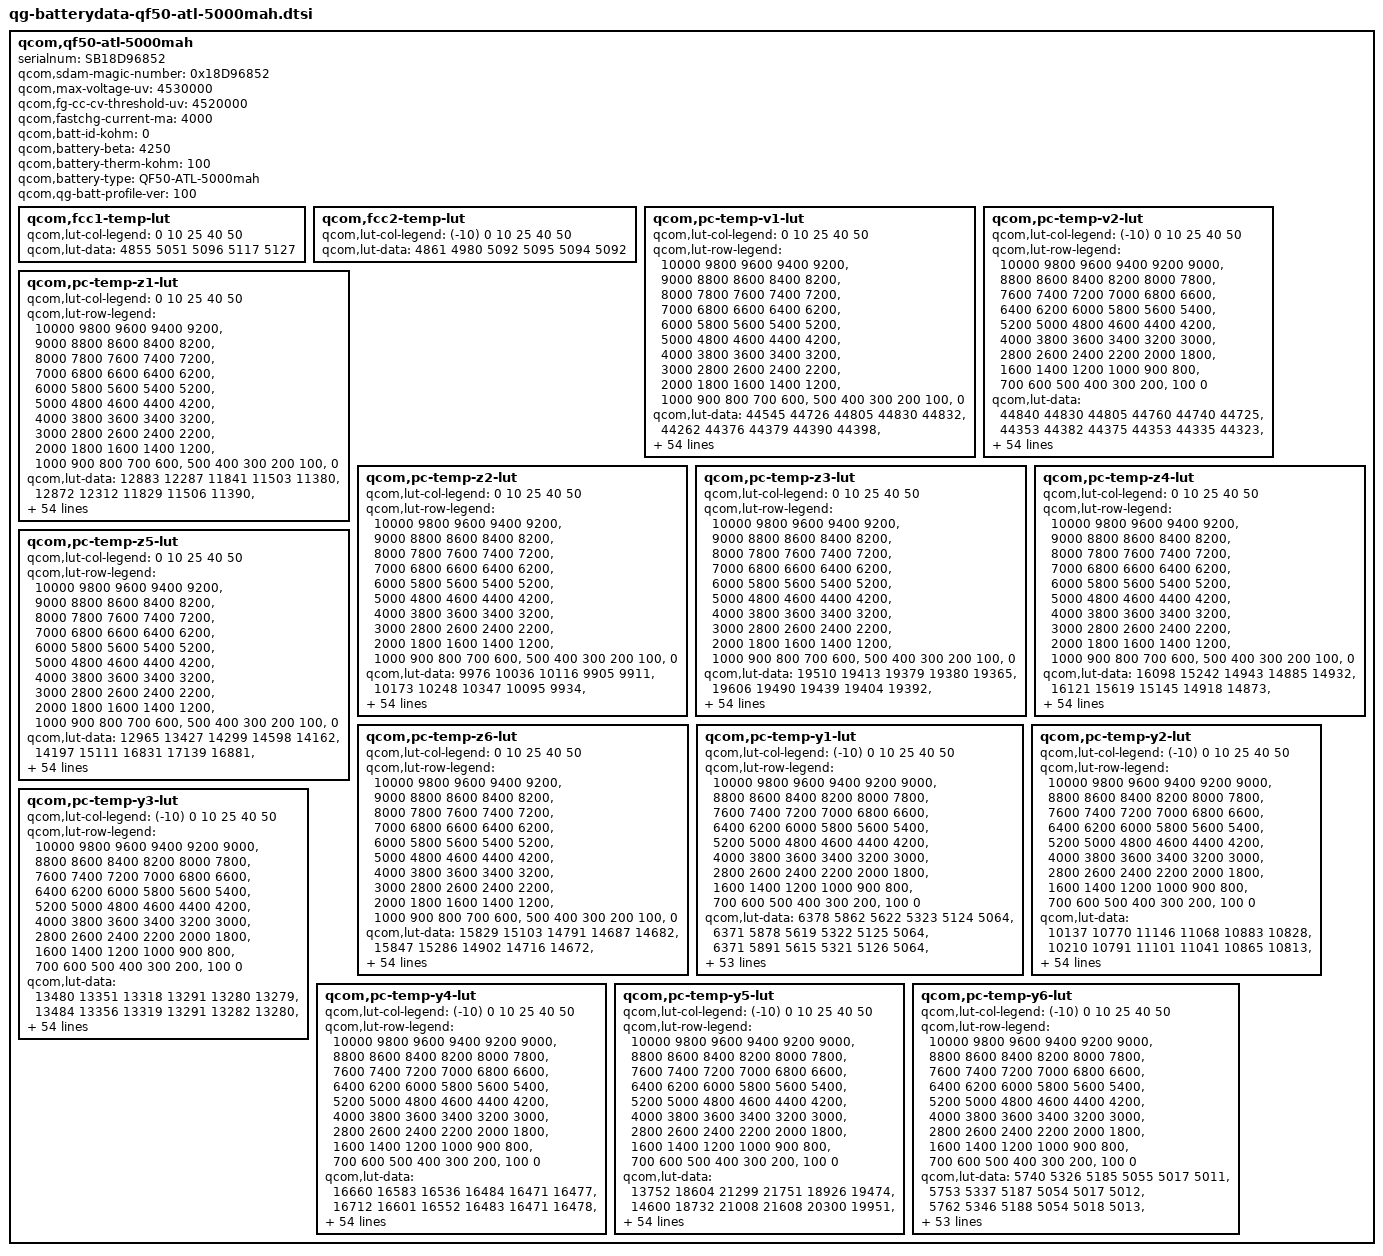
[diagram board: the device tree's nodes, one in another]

qcom,qf50-atl-5000mah {
    /* ATL_5000mAH_averaged_MasterSlave_Aug11th2023 */
    serialnum = "SB18D96852";
    qcom,sdam-magic-number = <0x18D96852>;
    qcom,max-voltage-uv = <4530000>;
    qcom,fg-cc-cv-threshold-uv = <4520000>;
    qcom,fastchg-current-ma = <4000>;
    qcom,batt-id-kohm = <0>;
    qcom,battery-beta = <4250>;
    qcom,battery-therm-kohm = <100>;
    qcom,battery-type = "QF50-ATL-5000mah";
    qcom,qg-batt-profile-ver = <100>;

	qcom,fcc1-temp-lut {
		qcom,lut-col-legend = <0 10 25 40 50>;
		qcom,lut-data = <4855 5051 5096 5117 5127>;
	};

	qcom,fcc2-temp-lut {
		qcom,lut-col-legend = <(-10) 0 10 25 40 50>;
		qcom,lut-data = <4861 4980 5092 5095 5094 5092>;
	};

	qcom,pc-temp-v1-lut {
		qcom,lut-col-legend = <0 10 25 40 50>;
		qcom,lut-row-legend = <10000 9800 9600 9400 9200>,
			<9000 8800 8600 8400 8200>,
			<8000 7800 7600 7400 7200>,
			<7000 6800 6600 6400 6200>,
			<6000 5800 5600 5400 5200>,
			<5000 4800 4600 4400 4200>,
			<4000 3800 3600 3400 3200>,
			<3000 2800 2600 2400 2200>,
			<2000 1800 1600 1400 1200>,
			<1000 900 800 700 600>,
			<500 400 300 200 100>,
			<0>;
		qcom,lut-data = <44545 44726 44805 44830 44832>,
			<44262 44376 44379 44390 44398>,
			<44026 44128 44112 44109 44110>,
			<43813 43903 43890 43882 43873>,
			<43593 43676 43664 43656 43646>,
			<43363 43455 43443 43433 43427>,
			<43128 43220 43216 43207 43206>,
			<42888 42974 42976 42969 42971>,
			<42641 42725 42729 42725 42725>,
			<42397 42479 42480 42479 42479>,
			<42157 42232 42228 42228 42232>,
			<41920 41987 41981 41981 41988>,
			<41688 41740 41737 41741 41746>,
			<41460 41501 41499 41505 41507>,
			<41239 41271 41269 41273 41276>,
			<41027 41048 41045 41045 41049>,
			<40821 40835 40831 40827 40830>,
			<40622 40630 40625 40619 40619>,
			<40431 40435 40429 40421 40418>,
			<40247 40252 40246 40239 40231>,
			<40068 40073 40071 40068 40057>,
			<39895 39890 39880 39875 39863>,
			<39720 39707 39668 39640 39625>,
			<39547 39499 39453 39408 39391>,
			<39369 39224 39229 39209 39202>,
			<39165 38972 39016 39028 39037>,
			<38941 38840 38875 38890 38896>,
			<38775 38751 38780 38786 38775>,
			<38672 38666 38692 38690 38668>,
			<38591 38580 38598 38587 38568>,
			<38519 38501 38509 38488 38478>,
			<38454 38426 38427 38405 38398>,
			<38397 38355 38350 38333 38326>,
			<38343 38293 38280 38265 38257>,
			<38296 38240 38221 38201 38189>,
			<38255 38191 38166 38139 38121>,
			<38221 38150 38112 38074 38051>,
			<38185 38112 38060 38009 37980>,
			<38142 38060 37996 37930 37894>,
			<38093 37985 37913 37827 37773>,
			<38025 37892 37814 37711 37639>,
			<37921 37780 37699 37600 37520>,
			<37798 37643 37564 37481 37401>,
			<37656 37475 37401 37317 37231>,
			<37490 37310 37241 37169 37087>,
			<37317 37180 37126 37073 37011>,
			<37241 37134 37083 37040 36983>,
			<37181 37107 37054 37014 36958>,
			<37141 37077 37027 36988 36930>,
			<37106 37042 36985 36943 36876>,
			<37060 36899 36816 36724 36630>,
			<37006 36480 36387 36301 36201>,
			<36858 35880 35800 35725 35623>,
			<36390 35022 34993 34937 34829>,
			<35518 33587 33735 33717 33593>,
			<30000 30000 30000 30000 30000>;
	};

	qcom,pc-temp-v2-lut {
		qcom,lut-col-legend = <(-10) 0 10 25 40 50>;
		qcom,lut-row-legend = <10000 9800 9600 9400 9200 9000>,
			<8800 8600 8400 8200 8000 7800>,
			<7600 7400 7200 7000 6800 6600>,
			<6400 6200 6000 5800 5600 5400>,
			<5200 5000 4800 4600 4400 4200>,
			<4000 3800 3600 3400 3200 3000>,
			<2800 2600 2400 2200 2000 1800>,
			<1600 1400 1200 1000 900 800>,
			<700 600 500 400 300 200>,
			<100 0>;
		qcom,lut-data = <44840 44830 44805 44760 44740 44725>,
			<44353 44382 44375 44353 44335 44323>,
			<43947 44007 44012 44005 43989 43978>,
			<43649 43725 43735 43730 43714 43704>,
			<43432 43515 43522 43514 43496 43485>,
			<43230 43311 43309 43297 43278 43267>,
			<43003 43082 43076 43063 43044 43035>,
			<42771 42847 42837 42823 42805 42798>,
			<42536 42608 42591 42578 42560 42556>,
			<42295 42361 42338 42327 42307 42309>,
			<42055 42114 42087 42078 42058 42062>,
			<41823 41871 41840 41831 41814 41816>,
			<41598 41631 41595 41588 41574 41573>,
			<41370 41398 41356 41349 41338 41336>,
			<41142 41171 41121 41116 41107 41105>,
			<40909 40952 40895 40890 40882 40880>,
			<40664 40746 40675 40672 40663 40662>,
			<40407 40544 40465 40463 40453 40452>,
			<40154 40317 40274 40265 40257 40254>,
			<39911 40056 40091 40074 40069 40065>,
			<39675 39800 39875 39879 39884 39881>,
			<39460 39563 39604 39680 39709 39712>,
			<39263 39338 39342 39472 39521 39528>,
			<39073 39137 39124 39230 39275 39283>,
			<38882 38953 38928 38982 39010 39017>,
			<38693 38787 38762 38798 38821 38829>,
			<38529 38640 38617 38658 38682 38695>,
			<38381 38506 38488 38537 38563 38576>,
			<38257 38378 38372 38427 38451 38461>,
			<38166 38252 38266 38328 38350 38355>,
			<38094 38142 38169 38236 38261 38262>,
			<38027 38050 38079 38149 38181 38179>,
			<37964 37973 37998 38071 38106 38103>,
			<37904 37909 37927 38000 38036 38038>,
			<37843 37857 37862 37932 37967 37973>,
			<37781 37810 37805 37861 37889 37889>,
			<37718 37763 37755 37789 37804 37787>,
			<37653 37716 37699 37710 37712 37680>,
			<37585 37660 37633 37623 37608 37570>,
			<37513 37590 37557 37531 37501 37460>,
			<37438 37506 37458 37440 37408 37364>,
			<37356 37393 37337 37343 37317 37270>,
			<37264 37259 37199 37217 37199 37149>,
			<37164 37126 37038 37076 37063 37009>,
			<37059 36973 36849 36940 36933 36883>,
			<36958 36815 36735 36866 36870 36821>,
			<36911 36753 36692 36846 36856 36807>,
			<36862 36699 36638 36826 36842 36791>,
			<36813 36653 36569 36796 36817 36764>,
			<36763 36601 36456 36724 36753 36688>,
			<36696 36506 36169 36463 36491 36397>,
			<36614 36313 35546 35958 36008 35899>,
			<36500 35974 34682 35266 35353 35231>,
			<36161 35224 33739 34296 34425 34285>,
			<35888 34573 32388 32686 32977 32845>,
			<35789 33816 28029 28977 28510 28219>;
	};

	qcom,pc-temp-z1-lut {
		qcom,lut-col-legend = <0 10 25 40 50>;
		qcom,lut-row-legend = <10000 9800 9600 9400 9200>,
			<9000 8800 8600 8400 8200>,
			<8000 7800 7600 7400 7200>,
			<7000 6800 6600 6400 6200>,
			<6000 5800 5600 5400 5200>,
			<5000 4800 4600 4400 4200>,
			<4000 3800 3600 3400 3200>,
			<3000 2800 2600 2400 2200>,
			<2000 1800 1600 1400 1200>,
			<1000 900 800 700 600>,
			<500 400 300 200 100>,
			<0>;
		qcom,lut-data = <12883 12287 11841 11503 11380>,
			<12872 12312 11829 11506 11390>,
			<12871 12301 11819 11497 11385>,
			<12878 12287 11813 11491 11381>,
			<12883 12275 11803 11485 11377>,
			<12877 12261 11791 11478 11373>,
			<12865 12243 11779 11472 11370>,
			<12838 12220 11767 11468 11369>,
			<12793 12200 11756 11465 11368>,
			<12766 12182 11751 11463 11367>,
			<12756 12167 11747 11461 11366>,
			<12748 12160 11744 11460 11365>,
			<12733 12155 11741 11459 11364>,
			<12708 12154 11739 11458 11363>,
			<12687 12151 11738 11457 11363>,
			<12670 12147 11738 11456 11363>,
			<12657 12147 11737 11456 11363>,
			<12655 12148 11736 11455 11363>,
			<12664 12149 11736 11455 11364>,
			<12673 12151 11738 11456 11364>,
			<12674 12153 11742 11458 11365>,
			<12672 12156 11743 11458 11365>,
			<12675 12161 11743 11458 11365>,
			<12690 12163 11743 11458 11365>,
			<12706 12163 11746 11459 11365>,
			<12713 12163 11750 11461 11367>,
			<12719 12167 11754 11464 11369>,
			<12723 12177 11758 11467 11371>,
			<12726 12185 11762 11471 11374>,
			<12728 12190 11767 11474 11376>,
			<12735 12194 11772 11477 11379>,
			<12744 12197 11778 11481 11381>,
			<12755 12203 11784 11484 11384>,
			<12771 12208 11790 11488 11387>,
			<12789 12218 11796 11492 11391>,
			<12799 12229 11803 11497 11395>,
			<12806 12241 11808 11502 11399>,
			<12810 12252 11813 11508 11403>,
			<12811 12260 11820 11514 11406>,
			<12811 12266 11830 11519 11410>,
			<12816 12272 11840 11524 11414>,
			<12849 12287 11842 11529 11418>,
			<12874 12304 11844 11534 11422>,
			<12884 12310 11855 11539 11425>,
			<12899 12321 11874 11544 11428>,
			<12928 12334 11880 11547 11430>,
			<12919 12330 11882 11546 11429>,
			<12931 12336 11880 11546 11429>,
			<12944 12332 11889 11548 11431>,
			<12943 12343 11898 11553 11436>,
			<12915 12361 11905 11560 11439>,
			<12947 12371 11921 11567 11446>,
			<12953 12391 11941 11577 11454>,
			<12970 12538 11960 11591 11466>,
			<12970 12538 11960 11591 11466>,
			<12970 12538 11960 11591 11466>;
	};

	qcom,pc-temp-z2-lut {
		qcom,lut-col-legend = <0 10 25 40 50>;
		qcom,lut-row-legend = <10000 9800 9600 9400 9200>,
			<9000 8800 8600 8400 8200>,
			<8000 7800 7600 7400 7200>,
			<7000 6800 6600 6400 6200>,
			<6000 5800 5600 5400 5200>,
			<5000 4800 4600 4400 4200>,
			<4000 3800 3600 3400 3200>,
			<3000 2800 2600 2400 2200>,
			<2000 1800 1600 1400 1200>,
			<1000 900 800 700 600>,
			<500 400 300 200 100>,
			<0>;
		qcom,lut-data = <9976 10036 10116 9905 9911>,
			<10173 10248 10347 10095 9934>,
			<10194 10308 10347 10167 10048>,
			<10200 10326 10338 10176 10191>,
			<10199 10307 10322 10177 10235>,
			<10184 10271 10284 10180 10194>,
			<10164 10244 10243 10176 10141>,
			<10145 10222 10199 10143 10107>,
			<10126 10211 10165 10098 10078>,
			<10112 10353 10163 10085 10055>,
			<10101 10533 10168 10088 10028>,
			<10093 10494 10170 10088 10002>,
			<10092 10288 10164 10064 9973>,
			<10092 10193 10159 10034 9947>,
			<10095 10203 10163 10033 9946>,
			<10104 10215 10172 10044 9963>,
			<10120 10225 10175 10049 9979>,
			<10133 10235 10172 10031 9991>,
			<10144 10245 10170 10011 10001>,
			<10156 10259 10172 10012 10007>,
			<10170 10274 10180 10019 10010>,
			<10186 10287 10196 10041 10023>,
			<10201 10298 10242 10182 10156>,
			<10216 10311 10273 10305 10287>,
			<10231 10328 10247 10240 10242>,
			<10249 10341 10202 10095 10115>,
			<10269 10332 10187 10064 10116>,
			<10277 10303 10182 10126 10483>,
			<10275 10292 10180 10175 10772>,
			<10273 10293 10195 10225 10642>,
			<10273 10296 10219 10296 10359>,
			<10275 10300 10232 10276 10163>,
			<10278 10306 10242 10117 10000>,
			<10283 10312 10245 10015 9930>,
			<10289 10320 10235 10001 9934>,
			<10295 10328 10223 9996 9942>,
			<10300 10336 10224 10008 9960>,
			<10306 10344 10234 10045 10000>,
			<10312 10356 10245 10079 10043>,
			<10320 10374 10262 10109 10094>,
			<10328 10387 10280 10131 10133>,
			<10337 10384 10291 10141 10131>,
			<10347 10381 10301 10145 10123>,
			<10360 10383 10308 10142 10125>,
			<10503 10422 10313 10143 10126>,
			<10531 10479 10301 10140 10100>,
			<10518 10469 10293 10135 10085>,
			<10527 10503 10280 10136 10088>,
			<10600 10539 10269 10144 10104>,
			<10436 10876 10288 10182 10150>,
			<10390 10719 10300 10152 10107>,
			<10160 10449 10263 10060 9980>,
			<10121 10372 10243 10010 9917>,
			<10084 10292 10148 9967 9862>,
			<10084 10292 10148 9967 9862>,
			<10084 10292 10148 9967 9862>;
	};

	qcom,pc-temp-z3-lut {
		qcom,lut-col-legend = <0 10 25 40 50>;
		qcom,lut-row-legend = <10000 9800 9600 9400 9200>,
			<9000 8800 8600 8400 8200>,
			<8000 7800 7600 7400 7200>,
			<7000 6800 6600 6400 6200>,
			<6000 5800 5600 5400 5200>,
			<5000 4800 4600 4400 4200>,
			<4000 3800 3600 3400 3200>,
			<3000 2800 2600 2400 2200>,
			<2000 1800 1600 1400 1200>,
			<1000 900 800 700 600>,
			<500 400 300 200 100>,
			<0>;
		qcom,lut-data = <19510 19413 19379 19380 19365>,
			<19606 19490 19439 19404 19392>,
			<19639 19518 19446 19410 19405>,
			<19658 19530 19448 19410 19410>,
			<19664 19533 19449 19411 19412>,
			<19668 19534 19449 19418 19413>,
			<19670 19534 19448 19423 19413>,
			<19669 19532 19447 19423 19414>,
			<19664 19531 19446 19423 19416>,
			<19659 19536 19444 19422 19416>,
			<19653 19540 19441 19418 19411>,
			<19646 19534 19438 19413 19406>,
			<19640 19515 19435 19408 19403>,
			<19634 19502 19432 19403 19400>,
			<19627 19498 19428 19401 19397>,
			<19618 19496 19425 19399 19394>,
			<19608 19493 19422 19397 19390>,
			<19601 19489 19418 19393 19387>,
			<19594 19486 19415 19389 19383>,
			<19589 19482 19411 19383 19379>,
			<19585 19479 19409 19377 19374>,
			<19582 19478 19409 19375 19372>,
			<19582 19479 19414 19384 19377>,
			<19583 19479 19418 19391 19381>,
			<19584 19486 19415 19384 19375>,
			<19588 19492 19410 19370 19362>,
			<19597 19491 19406 19368 19362>,
			<19601 19484 19402 19378 19400>,
			<19597 19480 19400 19390 19430>,
			<19591 19479 19405 19403 19427>,
			<19588 19479 19413 19414 19420>,
			<19584 19480 19418 19415 19412>,
			<19582 19481 19421 19406 19402>,
			<19580 19482 19423 19397 19392>,
			<19578 19481 19420 19389 19382>,
			<19576 19479 19414 19381 19373>,
			<19573 19477 19410 19374 19364>,
			<19570 19474 19405 19367 19355>,
			<19566 19472 19401 19364 19352>,
			<19561 19468 19400 19366 19354>,
			<19555 19464 19398 19369 19357>,
			<19549 19460 19395 19367 19359>,
			<19543 19456 19392 19364 19362>,
			<19534 19455 19391 19367 19365>,
			<19498 19445 19388 19366 19363>,
			<19484 19429 19379 19359 19356>,
			<19483 19429 19380 19355 19352>,
			<19472 19408 19372 19345 19339>,
			<19381 19390 19369 19343 19335>,
			<19283 19336 19366 19335 19326>,
			<19280 19349 19367 19349 19334>,
			<19268 19425 19382 19364 19353>,
			<19272 19433 19386 19365 19354>,
			<19396 19454 19388 19367 19356>,
			<19396 19454 19388 19367 19356>,
			<19396 19454 19388 19367 19356>;
	};

	qcom,pc-temp-z4-lut {
		qcom,lut-col-legend = <0 10 25 40 50>;
		qcom,lut-row-legend = <10000 9800 9600 9400 9200>,
			<9000 8800 8600 8400 8200>,
			<8000 7800 7600 7400 7200>,
			<7000 6800 6600 6400 6200>,
			<6000 5800 5600 5400 5200>,
			<5000 4800 4600 4400 4200>,
			<4000 3800 3600 3400 3200>,
			<3000 2800 2600 2400 2200>,
			<2000 1800 1600 1400 1200>,
			<1000 900 800 700 600>,
			<500 400 300 200 100>,
			<0>;
		qcom,lut-data = <16098 15242 14943 14885 14932>,
			<16121 15619 15145 14918 14873>,
			<15954 15390 15076 14925 14903>,
			<15633 15166 14953 14869 14858>,
			<15405 15054 14887 14828 14822>,
			<15261 14970 14844 14800 14800>,
			<15149 14909 14812 14778 14782>,
			<15063 14863 14785 14758 14764>,
			<14994 14822 14764 14742 14748>,
			<14938 14774 14745 14732 14741>,
			<14893 14735 14728 14726 14739>,
			<14856 14725 14717 14721 14736>,
			<14824 14727 14712 14717 14733>,
			<14798 14726 14707 14714 14730>,
			<14777 14720 14703 14710 14727>,
			<14760 14714 14699 14706 14724>,
			<14746 14709 14696 14703 14721>,
			<14739 14705 14693 14700 14718>,
			<14734 14701 14691 14697 14715>,
			<14731 14697 14686 14691 14709>,
			<14727 14693 14682 14682 14699>,
			<14722 14694 14683 14681 14697>,
			<14721 14698 14699 14706 14725>,
			<14723 14708 14724 14742 14764>,
			<14728 14760 14764 14778 14793>,
			<14748 14813 14809 14814 14820>,
			<14792 14812 14814 14818 14821>,
			<14813 14795 14799 14790 14765>,
			<14810 14778 14781 14757 14717>,
			<14804 14764 14762 14732 14711>,
			<14797 14750 14742 14711 14708>,
			<14788 14739 14726 14701 14704>,
			<14778 14730 14714 14697 14699>,
			<14771 14723 14705 14692 14693>,
			<14764 14720 14700 14685 14686>,
			<14756 14716 14695 14679 14679>,
			<14748 14712 14692 14676 14675>,
			<14739 14707 14689 14673 14672>,
			<14728 14702 14688 14673 14671>,
			<14716 14699 14688 14682 14686>,
			<14706 14695 14688 14691 14703>,
			<14698 14688 14686 14689 14699>,
			<14689 14678 14680 14683 14689>,
			<14676 14670 14675 14685 14696>,
			<14659 14656 14663 14680 14695>,
			<14660 14644 14649 14657 14663>,
			<14662 14639 14643 14653 14655>,
			<14671 14652 14639 14648 14649>,
			<14771 14666 14628 14631 14632>,
			<14877 14720 14621 14621 14619>,
			<14877 14707 14627 14641 14662>,
			<14889 14638 14639 14662 14685>,
			<14886 14642 14644 14671 14697>,
			<14789 14655 14653 14678 14705>,
			<14789 14655 14653 14678 14705>,
			<14789 14655 14653 14678 14705>;
	};

	qcom,pc-temp-z5-lut {
		qcom,lut-col-legend = <0 10 25 40 50>;
		qcom,lut-row-legend = <10000 9800 9600 9400 9200>,
			<9000 8800 8600 8400 8200>,
			<8000 7800 7600 7400 7200>,
			<7000 6800 6600 6400 6200>,
			<6000 5800 5600 5400 5200>,
			<5000 4800 4600 4400 4200>,
			<4000 3800 3600 3400 3200>,
			<3000 2800 2600 2400 2200>,
			<2000 1800 1600 1400 1200>,
			<1000 900 800 700 600>,
			<500 400 300 200 100>,
			<0>;
		qcom,lut-data = <12965 13427 14299 14598 14162>,
			<14197 15111 16831 17139 16881>,
			<14976 16289 17916 18251 17987>,
			<15573 17257 19012 19376 20816>,
			<16190 18104 19766 20671 22696>,
			<16878 18859 20356 22263 23560>,
			<17607 19647 20893 23734 24390>,
			<18350 20499 21471 24825 25921>,
			<19108 21574 22174 25761 27740>,
			<19899 23985 23185 26731 28317>,
			<20702 26450 24577 27838 28254>,
			<21576 26719 25687 28354 28202>,
			<22683 25813 26520 28224 28415>,
			<24071 25586 27183 28036 28820>,
			<25348 26395 27789 28507 29349>,
			<26528 27485 28481 30364 30177>,
			<27659 28480 28698 31566 31124>,
			<28323 29487 28955 32297 32156>,
			<28918 30465 29368 32854 33334>,
			<29457 31306 29945 32813 34706>,
			<30224 32235 30923 32573 36304>,
			<31850 33678 32692 32873 37911>,
			<33940 35780 36964 38189 40035>,
			<37158 38040 39732 42972 41538>,
			<41164 40979 36175 37180 36321>,
			<46372 43157 29366 24649 23829>,
			<52756 40834 25450 21008 20826>,
			<55183 33836 22731 20996 28485>,
			<50950 30752 21629 21392 35276>,
			<44837 30389 22615 25642 36515>,
			<41943 30228 24676 31967 36967>,
			<40070 31161 27321 32995 36403>,
			<39300 33936 31180 32446 34563>,
			<39452 36386 34044 32061 33005>,
			<39801 38503 35848 31943 32123>,
			<40135 40234 37016 31870 31422>,
			<40447 41422 37323 31939 30898>,
			<40808 42368 37415 32326 30323>,
			<41670 42739 37562 33084 30430>,
			<42961 42672 37794 37099 34033>,
			<43476 42276 37940 41001 37775>,
			<43039 40638 36440 38028 36990>,
			<42255 38817 33859 31822 34900>,
			<39980 41049 35209 35119 38355>,
			<38092 41263 37404 37168 40748>,
			<35083 36672 33177 33602 35286>,
			<33187 36846 33752 28519 29488>,
			<30194 23579 28263 23452 22318>,
			<20593 20631 29284 27160 24830>,
			<11533 13570 30890 26623 27880>,
			<11458 14208 29296 38678 29186>,
			<11281 33440 32439 26555 21352>,
			<11866 33621 30786 21742 17793>,
			<26696 45036 26861 18658 15426>,
			<26696 45036 26861 18658 15426>,
			<26696 45036 26861 18658 15426>;
	};

	qcom,pc-temp-z6-lut {
		qcom,lut-col-legend = <0 10 25 40 50>;
		qcom,lut-row-legend = <10000 9800 9600 9400 9200>,
			<9000 8800 8600 8400 8200>,
			<8000 7800 7600 7400 7200>,
			<7000 6800 6600 6400 6200>,
			<6000 5800 5600 5400 5200>,
			<5000 4800 4600 4400 4200>,
			<4000 3800 3600 3400 3200>,
			<3000 2800 2600 2400 2200>,
			<2000 1800 1600 1400 1200>,
			<1000 900 800 700 600>,
			<500 400 300 200 100>,
			<0>;
		qcom,lut-data = <15829 15103 14791 14687 14682>,
			<15847 15286 14902 14716 14672>,
			<15777 15187 14872 14721 14689>,
			<15616 15086 14816 14695 14672>,
			<15494 15029 14784 14678 14658>,
			<15413 14984 14762 14668 14649>,
			<15347 14948 14744 14660 14641>,
			<15291 14919 14729 14652 14634>,
			<15242 14894 14717 14644 14629>,
			<15201 14871 14705 14638 14625>,
			<15166 14851 14695 14633 14620>,
			<15135 14836 14688 14628 14617>,
			<15108 14824 14683 14623 14613>,
			<15084 14815 14679 14619 14610>,
			<15064 14809 14675 14615 14607>,
			<15046 14805 14671 14612 14603>,
			<15032 14800 14668 14609 14600>,
			<15024 14796 14664 14606 14597>,
			<15020 14792 14661 14602 14593>,
			<15017 14788 14658 14596 14588>,
			<15015 14786 14655 14589 14581>,
			<15014 14786 14656 14588 14579>,
			<15014 14789 14665 14604 14594>,
			<15016 14795 14679 14622 14613>,
			<15022 14822 14695 14634 14621>,
			<15036 14849 14712 14643 14626>,
			<15061 14849 14714 14644 14627>,
			<15072 14839 14707 14638 14625>,
			<15071 14832 14699 14631 14621>,
			<15068 14827 14695 14629 14618>,
			<15065 14823 14691 14626 14613>,
			<15062 14820 14688 14623 14608>,
			<15060 14818 14686 14617 14601>,
			<15060 14817 14683 14610 14593>,
			<15060 14817 14680 14604 14585>,
			<15059 14817 14677 14597 14578>,
			<15058 14816 14674 14593 14572>,
			<15057 14815 14671 14588 14566>,
			<15057 14815 14671 14587 14564>,
			<15057 14815 14672 14592 14571>,
			<15058 14816 14673 14598 14579>,
			<15061 14815 14672 14597 14579>,
			<15065 14813 14670 14593 14577>,
			<15069 14815 14670 14596 14581>,
			<15064 14812 14667 14594 14581>,
			<15065 14803 14659 14581 14564>,
			<15067 14802 14657 14578 14558>,
			<15066 14798 14652 14571 14550>,
			<15064 14796 14646 14563 14540>,
			<15063 14795 14644 14554 14530>,
			<15065 14801 14650 14571 14553>,
			<15071 14816 14667 14590 14575>,
			<15084 14831 14676 14598 14584>,
			<15117 14860 14689 14605 14592>,
			<15117 14860 14689 14605 14592>,
			<15117 14860 14689 14605 14592>;
	};

	qcom,pc-temp-y1-lut {
		qcom,lut-col-legend = <(-10) 0 10 25 40 50>;
		qcom,lut-row-legend = <10000 9800 9600 9400 9200 9000>,
			<8800 8600 8400 8200 8000 7800>,
			<7600 7400 7200 7000 6800 6600>,
			<6400 6200 6000 5800 5600 5400>,
			<5200 5000 4800 4600 4400 4200>,
			<4000 3800 3600 3400 3200 3000>,
			<2800 2600 2400 2200 2000 1800>,
			<1600 1400 1200 1000 900 800>,
			<700 600 500 400 300 200>,
			<100 0>;
		qcom,lut-data = <6378 5862 5622 5323 5124 5064>,
			<6371 5878 5619 5322 5125 5064>,
			<6371 5891 5615 5321 5126 5064>,
			<6375 5902 5611 5318 5126 5062>,
			<6380 5910 5607 5315 5125 5061>,
			<6383 5913 5605 5312 5124 5059>,
			<6385 5909 5604 5309 5122 5056>,
			<6389 5904 5604 5306 5118 5054>,
			<6391 5904 5603 5303 5115 5052>,
			<6395 5910 5602 5299 5113 5052>,
			<6398 5914 5602 5295 5112 5051>,
			<6395 5913 5596 5293 5110 5049>,
			<6383 5910 5590 5291 5109 5048>,
			<6378 5907 5589 5289 5108 5048>,
			<6385 5905 5586 5287 5107 5048>,
			<6394 5902 5585 5286 5106 5048>,
			<6395 5901 5583 5287 5106 5048>,
			<6391 5900 5582 5288 5106 5049>,
			<6388 5902 5584 5288 5106 5049>,
			<6391 5913 5591 5288 5107 5049>,
			<6395 5922 5593 5289 5107 5049>,
			<6395 5919 5591 5292 5109 5050>,
			<6390 5911 5588 5295 5110 5050>,
			<6385 5908 5589 5297 5111 5051>,
			<6393 5909 5591 5299 5112 5052>,
			<6411 5909 5593 5302 5114 5053>,
			<6417 5912 5599 5307 5115 5054>,
			<6408 5919 5605 5311 5116 5055>,
			<6396 5923 5607 5313 5118 5057>,
			<6389 5926 5609 5315 5121 5059>,
			<6382 5927 5610 5318 5124 5061>,
			<6380 5927 5608 5323 5127 5062>,
			<6396 5925 5607 5327 5129 5064>,
			<6417 5925 5612 5330 5132 5066>,
			<6418 5927 5619 5334 5135 5068>,
			<6406 5929 5620 5338 5137 5069>,
			<6396 5928 5617 5343 5138 5070>,
			<6395 5923 5616 5346 5139 5071>,
			<6396 5921 5618 5348 5140 5072>,
			<6396 5920 5620 5349 5141 5073>,
			<6400 5921 5625 5349 5142 5074>,
			<6405 5924 5635 5348 5144 5075>,
			<6411 5930 5636 5353 5146 5077>,
			<6417 5940 5638 5359 5149 5078>,
			<6422 5942 5655 5362 5152 5082>,
			<6421 5945 5651 5370 5155 5083>,
			<6407 5953 5654 5375 5156 5082>,
			<6425 5954 5648 5382 5155 5083>,
			<6444 5964 5650 5380 5155 5084>,
			<6460 5993 5662 5381 5156 5085>,
			<6532 6046 5736 5391 5158 5086>,
			<6568 6121 5799 5396 5162 5089>,
			<6672 6208 5947 5424 5167 5095>,
			<6773 6267 5962 5464 5176 5103>,
			<6773 6267 5962 5464 5176 5103>,
			<6773 6267 5962 5464 5176 5103>;
	};

	qcom,pc-temp-y2-lut {
		qcom,lut-col-legend = <(-10) 0 10 25 40 50>;
		qcom,lut-row-legend = <10000 9800 9600 9400 9200 9000>,
			<8800 8600 8400 8200 8000 7800>,
			<7600 7400 7200 7000 6800 6600>,
			<6400 6200 6000 5800 5600 5400>,
			<5200 5000 4800 4600 4400 4200>,
			<4000 3800 3600 3400 3200 3000>,
			<2800 2600 2400 2200 2000 1800>,
			<1600 1400 1200 1000 900 800>,
			<700 600 500 400 300 200>,
			<100 0>;
		qcom,lut-data = <10137 10770 11146 11068 10883 10828>,
			<10210 10791 11101 11041 10865 10813>,
			<10292 10805 11057 11007 10829 10796>,
			<10374 10812 11017 10971 10788 10777>,
			<10444 10814 10980 10936 10752 10759>,
			<10490 10811 10950 10908 10731 10740>,
			<10512 10800 10924 10881 10717 10721>,
			<10527 10786 10902 10856 10704 10701>,
			<10542 10775 10880 10836 10690 10681>,
			<10557 10765 10860 10815 10660 10661>,
			<10574 10760 10847 10803 10644 10643>,
			<10601 10770 10838 10798 10641 10624>,
			<10642 10792 10833 10795 10638 10609>,
			<10682 10814 10839 10794 10634 10600>,
			<10723 10840 10863 10795 10628 10593>,
			<10759 10872 10891 10797 10622 10591>,
			<10779 10928 10927 10814 10614 10593>,
			<10793 10990 10972 10841 10609 10597>,
			<10804 11006 11043 10880 10626 10599>,
			<10817 11006 11129 10936 10678 10602>,
			<10827 11007 11146 10994 10746 10621>,
			<10828 11011 11101 11063 10879 10757>,
			<10817 11016 11064 11104 10968 10862>,
			<10796 11021 11073 11062 10919 10846>,
			<10642 11029 11094 10985 10829 10812>,
			<10323 11038 11112 10965 10810 10799>,
			<10148 11047 11130 10962 10815 10800>,
			<9914 11057 11145 10961 10823 10807>,
			<9713 11032 11157 10993 10847 10823>,
			<9695 10762 11167 11042 10882 10845>,
			<9691 10522 11174 11054 10899 10866>,
			<9687 10632 11179 11055 10913 10892>,
			<9683 10904 11181 11058 10920 10910>,
			<9679 10985 11180 11080 10925 10924>,
			<9676 10948 11177 11105 10931 10932>,
			<9673 10897 11167 11109 10922 10929>,
			<9670 10850 11136 11108 10896 10913>,
			<9668 10797 11101 11105 10884 10894>,
			<9667 10708 11067 11095 10889 10864>,
			<9666 10447 11022 11084 10897 10835>,
			<9665 10183 10946 11076 10898 10825>,
			<9664 9936 10833 11070 10899 10820>,
			<9663 9704 10729 11060 10885 10819>,
			<9662 9686 10576 11030 10868 10806>,
			<9661 9675 10176 10983 10837 10732>,
			<9659 9667 9926 10985 10757 10616>,
			<9657 9664 9778 10961 10701 10594>,
			<9656 9661 9698 10957 10727 10593>,
			<9653 9656 9668 10957 10763 10584>,
			<9650 9652 9656 10975 10739 10583>,
			<9649 9649 9652 10914 10697 10586>,
			<9648 9648 9651 10818 10654 10538>,
			<9648 9648 9650 10677 10568 10444>,
			<9648 9649 9651 10474 10439 10305>,
			<9648 9649 9651 10474 10439 10305>,
			<9648 9649 9651 10474 10439 10305>;
	};

	qcom,pc-temp-y3-lut {
		qcom,lut-col-legend = <(-10) 0 10 25 40 50>;
		qcom,lut-row-legend = <10000 9800 9600 9400 9200 9000>,
			<8800 8600 8400 8200 8000 7800>,
			<7600 7400 7200 7000 6800 6600>,
			<6400 6200 6000 5800 5600 5400>,
			<5200 5000 4800 4600 4400 4200>,
			<4000 3800 3600 3400 3200 3000>,
			<2800 2600 2400 2200 2000 1800>,
			<1600 1400 1200 1000 900 800>,
			<700 600 500 400 300 200>,
			<100 0>;
		qcom,lut-data = <13480 13351 13318 13291 13280 13279>,
			<13484 13356 13319 13291 13282 13280>,
			<13486 13360 13321 13292 13283 13281>,
			<13487 13363 13322 13293 13285 13282>,
			<13488 13367 13324 13294 13286 13283>,
			<13488 13369 13325 13295 13287 13284>,
			<13487 13371 13326 13296 13287 13284>,
			<13485 13373 13327 13296 13288 13285>,
			<13483 13374 13328 13297 13288 13286>,
			<13479 13374 13328 13297 13288 13286>,
			<13474 13375 13329 13298 13288 13287>,
			<13471 13374 13330 13298 13289 13288>,
			<13467 13372 13331 13299 13291 13288>,
			<13463 13370 13331 13300 13292 13289>,
			<13457 13367 13330 13300 13292 13290>,
			<13450 13365 13329 13301 13293 13291>,
			<13443 13365 13327 13302 13293 13291>,
			<13434 13365 13325 13303 13293 13292>,
			<13425 13364 13325 13302 13294 13292>,
			<13416 13358 13326 13301 13295 13293>,
			<13408 13352 13326 13300 13296 13293>,
			<13400 13347 13321 13300 13295 13293>,
			<13392 13343 13316 13300 13293 13292>,
			<13386 13340 13313 13298 13289 13288>,
			<13385 13337 13311 13293 13285 13283>,
			<13386 13335 13310 13291 13283 13282>,
			<13388 13332 13308 13290 13283 13282>,
			<13388 13330 13307 13289 13282 13283>,
			<13390 13327 13306 13289 13282 13282>,
			<13394 13321 13306 13290 13281 13281>,
			<13403 13317 13305 13290 13281 13280>,
			<13416 13317 13304 13289 13281 13279>,
			<13434 13319 13304 13289 13281 13279>,
			<13456 13322 13304 13289 13281 13281>,
			<13484 13324 13304 13289 13282 13283>,
			<13518 13326 13304 13289 13283 13283>,
			<13558 13329 13305 13289 13283 13283>,
			<13604 13333 13306 13289 13283 13282>,
			<13657 13338 13307 13289 13283 13282>,
			<13717 13347 13309 13288 13283 13282>,
			<13786 13358 13310 13289 13283 13283>,
			<13863 13372 13312 13289 13284 13284>,
			<13942 13391 13316 13289 13284 13283>,
			<14034 13426 13321 13289 13283 13282>,
			<14152 13485 13319 13287 13281 13281>,
			<14328 13580 13338 13291 13286 13286>,
			<14465 13680 13364 13293 13289 13288>,
			<14625 13866 13417 13295 13291 13290>,
			<15006 14266 13572 13298 13293 13292>,
			<16267 15608 14197 13300 13293 13291>,
			<19537 20170 16932 13298 13288 13289>,
			<28038 36692 29998 13299 13289 13292>,
			<53462 65535 65535 13307 13294 13294>,
			<65535 65535 65535 13329 13300 13304>,
			<65535 65535 65535 13329 13300 13304>,
			<65535 65535 65535 13329 13300 13304>;
	};

	qcom,pc-temp-y4-lut {
		qcom,lut-col-legend = <(-10) 0 10 25 40 50>;
		qcom,lut-row-legend = <10000 9800 9600 9400 9200 9000>,
			<8800 8600 8400 8200 8000 7800>,
			<7600 7400 7200 7000 6800 6600>,
			<6400 6200 6000 5800 5600 5400>,
			<5200 5000 4800 4600 4400 4200>,
			<4000 3800 3600 3400 3200 3000>,
			<2800 2600 2400 2200 2000 1800>,
			<1600 1400 1200 1000 900 800>,
			<700 600 500 400 300 200>,
			<100 0>;
		qcom,lut-data = <16660 16583 16536 16484 16471 16477>,
			<16712 16601 16552 16483 16471 16478>,
			<16793 16638 16570 16482 16472 16480>,
			<16881 16681 16586 16481 16472 16481>,
			<16957 16717 16597 16480 16472 16482>,
			<16999 16732 16600 16480 16472 16483>,
			<17010 16732 16598 16479 16472 16483>,
			<17015 16731 16593 16479 16471 16484>,
			<17018 16729 16587 16479 16471 16483>,
			<17018 16723 16581 16479 16470 16482>,
			<17019 16719 16579 16480 16469 16480>,
			<17023 16723 16580 16482 16470 16480>,
			<17032 16732 16582 16486 16472 16480>,
			<17036 16745 16587 16490 16474 16480>,
			<17032 16765 16600 16496 16476 16480>,
			<17023 16784 16616 16503 16480 16481>,
			<17005 16800 16640 16513 16484 16483>,
			<16965 16813 16667 16526 16491 16486>,
			<16921 16810 16694 16549 16499 16491>,
			<16881 16769 16720 16580 16510 16499>,
			<16842 16721 16720 16594 16529 16513>,
			<16808 16682 16663 16601 16567 16552>,
			<16779 16646 16599 16604 16593 16579>,
			<16750 16618 16560 16564 16557 16548>,
			<16712 16596 16528 16491 16489 16491>,
			<16673 16580 16514 16470 16469 16474>,
			<16650 16568 16506 16466 16464 16471>,
			<16636 16559 16502 16465 16463 16470>,
			<16628 16552 16501 16467 16465 16470>,
			<16629 16546 16501 16471 16469 16471>,
			<16631 16540 16500 16476 16474 16474>,
			<16634 16529 16497 16481 16483 16483>,
			<16637 16511 16496 16486 16493 16494>,
			<16640 16506 16495 16493 16502 16511>,
			<16645 16515 16495 16498 16510 16526>,
			<16652 16528 16498 16498 16510 16526>,
			<16660 16542 16509 16495 16509 16521>,
			<16669 16559 16520 16492 16507 16515>,
			<16678 16574 16531 16484 16496 16506>,
			<16682 16588 16538 16477 16484 16500>,
			<16685 16598 16538 16481 16489 16505>,
			<16686 16602 16536 16489 16501 16518>,
			<16683 16604 16536 16485 16496 16511>,
			<16677 16602 16534 16476 16477 16485>,
			<16678 16599 16523 16458 16447 16451>,
			<16678 16590 16538 16469 16464 16480>,
			<16675 16590 16559 16486 16499 16522>,
			<16671 16601 16588 16513 16540 16566>,
			<16680 16613 16628 16553 16579 16607>,
			<16778 16691 16688 16585 16601 16617>,
			<17099 17202 17194 16539 16528 16528>,
			<17930 20734 25139 16516 16491 16496>,
			<20772 44829 65535 16539 16487 16493>,
			<22519 65535 65535 16594 16487 16484>,
			<22519 65535 65535 16594 16487 16484>,
			<22519 65535 65535 16594 16487 16484>;
	};

	qcom,pc-temp-y5-lut {
		qcom,lut-col-legend = <(-10) 0 10 25 40 50>;
		qcom,lut-row-legend = <10000 9800 9600 9400 9200 9000>,
			<8800 8600 8400 8200 8000 7800>,
			<7600 7400 7200 7000 6800 6600>,
			<6400 6200 6000 5800 5600 5400>,
			<5200 5000 4800 4600 4400 4200>,
			<4000 3800 3600 3400 3200 3000>,
			<2800 2600 2400 2200 2000 1800>,
			<1600 1400 1200 1000 900 800>,
			<700 600 500 400 300 200>,
			<100 0>;
		qcom,lut-data = <13752 18604 21299 21751 18926 19474>,
			<14600 18732 21008 21608 20300 19951>,
			<15454 18838 20690 21437 21459 20594>,
			<16258 18929 20393 21249 22349 21246>,
			<16957 19009 20166 21061 22907 21748>,
			<17494 19083 20055 20884 23079 21943>,
			<17908 19157 20058 20647 22853 21906>,
			<18237 19212 20075 20341 22381 21835>,
			<18323 19186 19927 19968 21519 21810>,
			<18288 18938 19460 19432 19979 21791>,
			<18253 18594 18993 18962 19355 21743>,
			<18370 18082 18601 18535 19765 21362>,
			<18800 17530 18172 18076 20206 20847>,
			<19289 17401 17563 17545 20065 20526>,
			<19863 17440 16812 16931 19455 20243>,
			<20452 17541 16432 16486 18733 19864>,
			<20863 18635 16269 16176 17709 19230>,
			<21188 20602 16189 15931 16829 18511>,
			<21433 21664 17255 15700 16436 17756>,
			<21591 22223 19948 15487 16172 17005>,
			<21733 22677 21820 15918 16194 16770>,
			<21990 23177 23070 20058 17015 16851>,
			<22513 23613 23970 23570 18253 17085>,
			<23002 23777 24627 24142 20222 18411>,
			<22627 23794 25130 24453 22454 20727>,
			<21183 23843 25149 24252 22777 21929>,
			<19900 24011 24759 22830 21872 22632>,
			<16708 24211 24504 21918 20745 22918>,
			<13921 24133 24584 22140 19446 21208>,
			<13687 22045 24770 22457 18240 18395>,
			<13637 20121 25104 22476 17922 17255>,
			<13628 19989 25841 22368 17815 16656>,
			<13778 20308 26210 22347 17818 16464>,
			<13996 20900 26137 22903 18623 17890>,
			<14111 21380 25985 23850 20061 20139>,
			<14186 21848 25762 24882 21735 21601>,
			<14245 22501 25401 26122 23842 22818>,
			<14285 23243 25202 26547 24601 23223>,
			<14321 23558 25159 25902 24034 23158>,
			<14401 22865 25105 25017 23338 23031>,
			<14599 21729 24617 24340 23013 22663>,
			<14737 18761 23786 23783 22796 22096>,
			<14608 15463 23821 24211 24617 24139>,
			<14265 15232 23274 24112 25558 25347>,
			<13663 14715 17194 22896 22085 23116>,
			<13364 13938 16327 22963 19357 17174>,
			<13424 13923 15594 21366 17319 15360>,
			<13275 13636 14729 20051 16095 14451>,
			<12729 13796 14343 18858 15628 14157>,
			<11889 12807 13994 18265 15149 13868>,
			<10615 10664 11387 18539 15330 14832>,
			<9988 9398 9252 19423 16332 15430>,
			<9850 9034 8836 19100 16620 14682>,
			<13484 11104 8771 19397 17188 17110>,
			<13484 11104 8771 19397 17188 17110>,
			<13484 11104 8771 19397 17188 17110>;
	};

	qcom,pc-temp-y6-lut {
		qcom,lut-col-legend = <(-10) 0 10 25 40 50>;
		qcom,lut-row-legend = <10000 9800 9600 9400 9200 9000>,
			<8800 8600 8400 8200 8000 7800>,
			<7600 7400 7200 7000 6800 6600>,
			<6400 6200 6000 5800 5600 5400>,
			<5200 5000 4800 4600 4400 4200>,
			<4000 3800 3600 3400 3200 3000>,
			<2800 2600 2400 2200 2000 1800>,
			<1600 1400 1200 1000 900 800>,
			<700 600 500 400 300 200>,
			<100 0>;
		qcom,lut-data = <5740 5326 5185 5055 5017 5011>,
			<5753 5337 5187 5054 5017 5012>,
			<5762 5346 5188 5054 5018 5013>,
			<5768 5352 5188 5053 5020 5014>,
			<5771 5356 5187 5053 5020 5015>,
			<5772 5357 5186 5053 5021 5016>,
			<5770 5355 5183 5052 5021 5016>,
			<5763 5351 5179 5052 5021 5017>,
			<5757 5347 5175 5052 5021 5017>,
			<5751 5342 5171 5052 5021 5017>,
			<5745 5338 5169 5052 5020 5017>,
			<5743 5336 5168 5053 5021 5018>,
			<5741 5335 5167 5054 5023 5018>,
			<5738 5335 5168 5055 5024 5019>,
			<5734 5336 5169 5057 5025 5019>,
			<5727 5339 5171 5060 5027 5020>,
			<5718 5342 5176 5063 5028 5021>,
			<5703 5345 5181 5067 5030 5022>,
			<5688 5344 5188 5074 5033 5024>,
			<5674 5328 5196 5081 5037 5027>,
			<5660 5310 5196 5085 5043 5031>,
			<5652 5297 5176 5087 5053 5041>,
			<5646 5286 5154 5087 5059 5048>,
			<5641 5277 5141 5075 5046 5037>,
			<5633 5271 5132 5051 5023 5016>,
			<5624 5267 5128 5044 5016 5011>,
			<5619 5266 5126 5042 5014 5011>,
			<5621 5265 5125 5042 5014 5010>,
			<5625 5264 5125 5043 5014 5010>,
			<5635 5261 5126 5045 5015 5009>,
			<5655 5260 5127 5047 5016 5010>,
			<5678 5262 5128 5048 5019 5012>,
			<5704 5268 5129 5050 5022 5015>,
			<5735 5276 5131 5053 5026 5021>,
			<5770 5289 5134 5055 5029 5027>,
			<5809 5307 5139 5056 5029 5027>,
			<5852 5327 5146 5056 5029 5026>,
			<5897 5352 5155 5055 5029 5024>,
			<5947 5379 5165 5054 5026 5022>,
			<6000 5410 5176 5052 5022 5020>,
			<6057 5443 5187 5054 5024 5022>,
			<6120 5476 5200 5057 5029 5027>,
			<6187 5515 5220 5057 5027 5024>,
			<6267 5572 5246 5056 5022 5016>,
			<6373 5651 5264 5051 5012 5007>,
			<6532 5761 5327 5059 5021 5019>,
			<6657 5857 5393 5067 5034 5033>,
			<6806 6032 5498 5078 5047 5047>,
			<7159 6390 5711 5092 5060 5060>,
			<8222 7515 6288 5103 5066 5063>,
			<10728 10987 8549 5089 5041 5035>,
			<16865 23299 20036 5089 5033 5029>,
			<34756 65535 65535 5114 5036 5031>,
			<65535 65535 65535 5180 5042 5038>,
			<65535 65535 65535 5180 5042 5038>,
			<65535 65535 65535 5180 5042 5038>;
	};

};
